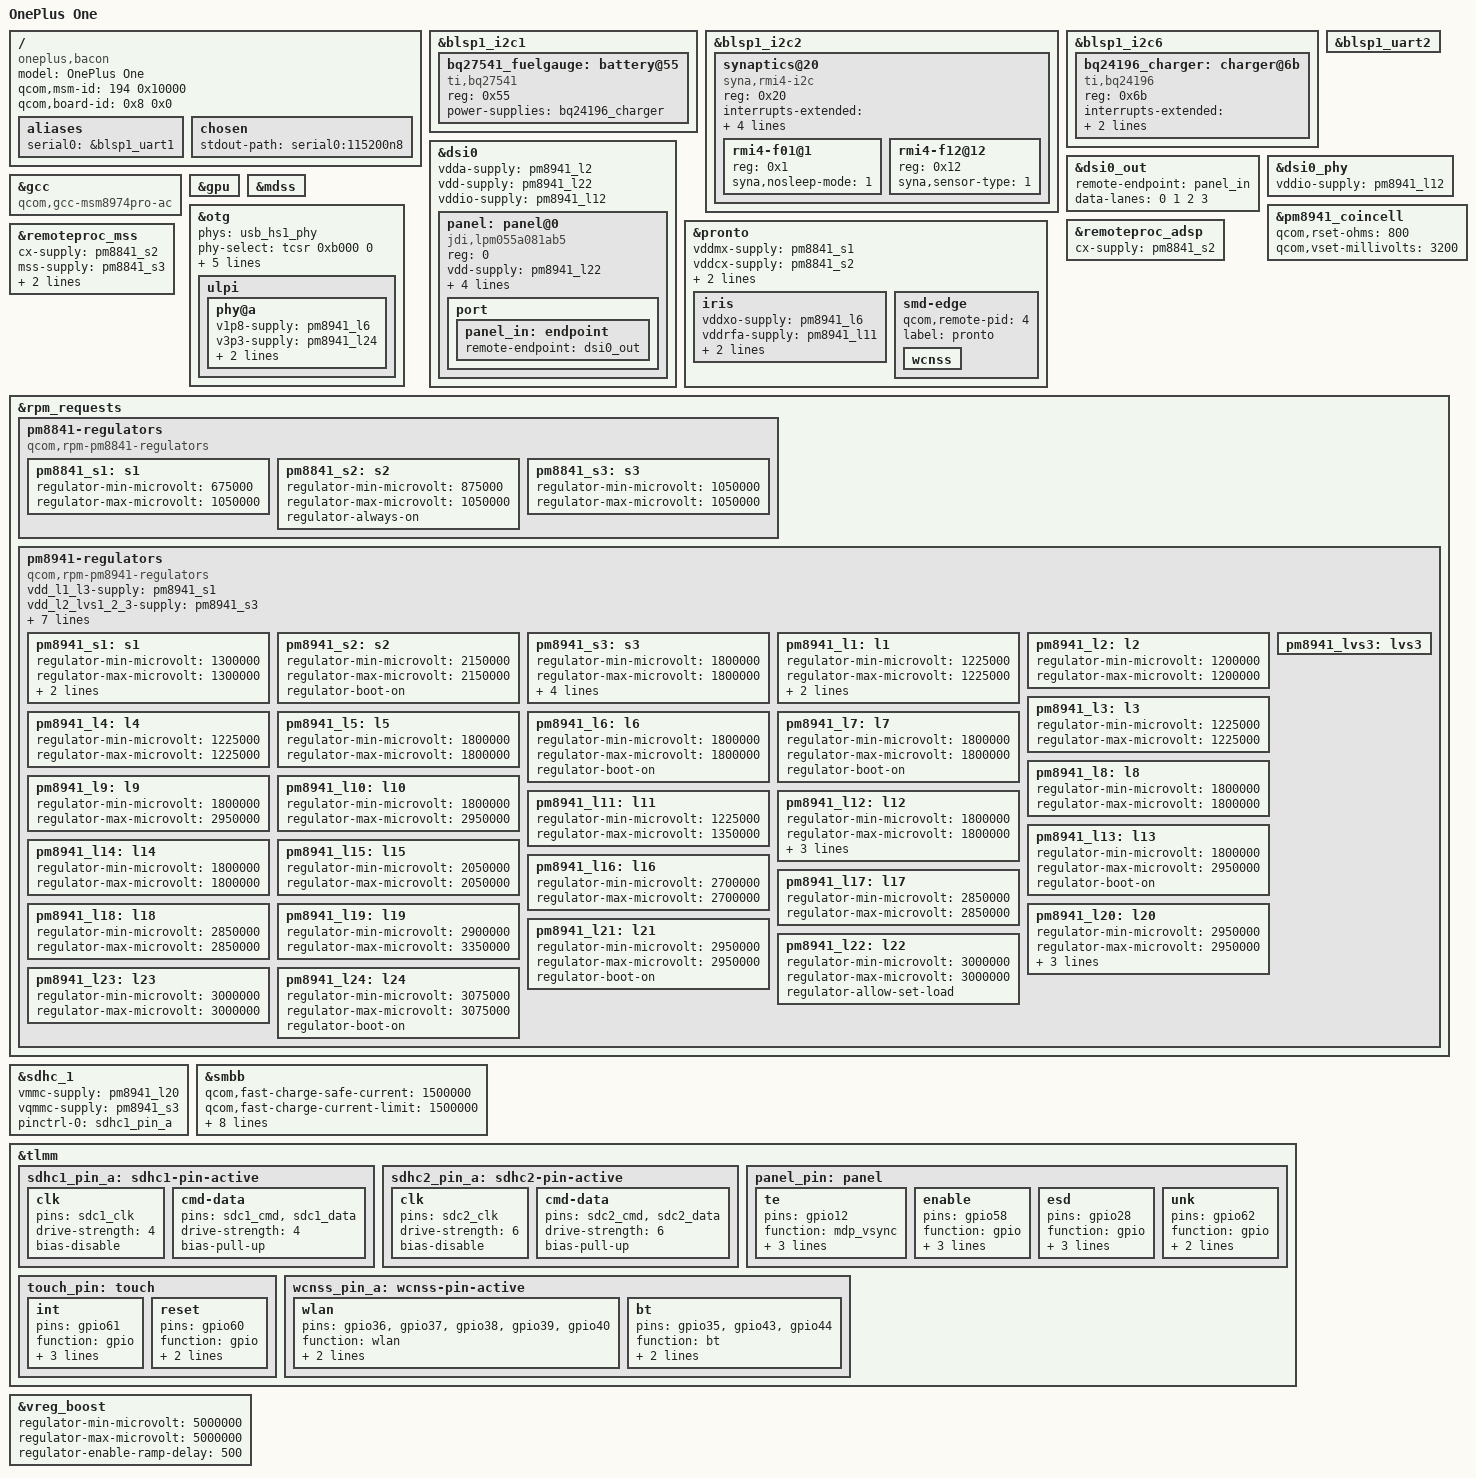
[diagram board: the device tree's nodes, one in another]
// SPDX-License-Identifier: GPL-2.0
#include "qcom-msm8974pro.dtsi"
#include "qcom-pm8841.dtsi"
#include "qcom-pm8941.dtsi"
#include <dt-bindings/input/input.h>
#include <dt-bindings/pinctrl/qcom,pmic-gpio.h>

/ {
	model = "OnePlus One";
	compatible = "oneplus,bacon", "qcom,msm8974";
	qcom,msm-id = <194 0x10000>;
	qcom,board-id = <0x8 0x0>;

	aliases {
		serial0 = &blsp1_uart1;
	};

	chosen {
		stdout-path = "serial0:115200n8";
	};
};

&blsp1_i2c1 {
	status = "okay";

	bq27541_fuelgauge: battery@55 {
		compatible = "ti,bq27541";
		reg = <0x55>;
		power-supplies = <&bq24196_charger>;
	};
};

&blsp1_i2c2 {
	status = "okay";

	synaptics@20 {
		compatible = "syna,rmi4-i2c";
		reg = <0x20>;

		interrupts-extended = <&tlmm 61 IRQ_TYPE_EDGE_FALLING>;
		vdd-supply = <&pm8941_l22>;
		vio-supply = <&pm8941_lvs3>;

		pinctrl-names = "default";
		pinctrl-0 = <&touch_pin>;

		#address-cells = <1>;
		#size-cells = <0>;

		rmi4-f01@1 {
			reg = <0x1>;
			syna,nosleep-mode = <1>;
		};

		rmi4-f12@12 {
			reg = <0x12>;
			syna,sensor-type = <1>;
		};

		// reset tlmm 8
		// other functions available ?
	};
};

&blsp1_i2c6 {
	status = "okay";

	bq24196_charger: charger@6b {
		compatible = "ti,bq24196";
		reg = <0x6b>;
		interrupts-extended = <&tlmm 31 IRQ_TYPE_EDGE_FALLING>;
		omit-battery-class;
	};
};

&blsp1_uart2 {
	status = "okay";
};

&dsi0 {
	status = "okay";

	vdda-supply = <&pm8941_l2>;
	vdd-supply = <&pm8941_l22>;
	vddio-supply = <&pm8941_l12>;

	panel: panel@0 {
		reg = <0>;
		compatible = "jdi,lpm055a081ab5";

		vdd-supply = <&pm8941_l22>;
		vddio-supply = <&pm8941_l12>;

		// backlight?

		enable-gpios = <&tlmm 58 0>;
		reset-gpios = <&pm8941_gpios 19 0>;

		pinctrl-names = "default";
		pinctrl-0 = <&panel_pin>;

		port {
			panel_in: endpoint {
				remote-endpoint = <&dsi0_out>;
			};
		};
	};
};

&dsi0_out {
	remote-endpoint = <&panel_in>;
	data-lanes = <0 1 2 3>;
};

&dsi0_phy {
    status = "okay";

    vddio-supply = <&pm8941_l12>;
};

&gcc {
	compatible = "qcom,gcc-msm8974pro-ac";
};

&gpu {
	status = "okay";
};

&mdss {
	status = "okay";
};

&otg {
	status = "okay";

	phys = <&usb_hs1_phy>;
	phy-select = <&tcsr 0xb000 0>;
	extcon = <&smbb>, <&usb_id>;
	vbus-supply = <&chg_otg>;

	hnp-disable;
	srp-disable;
	adp-disable;

	ulpi {
		phy@a {
			status = "okay";

			v1p8-supply = <&pm8941_l6>;
			v3p3-supply = <&pm8941_l24>;

			extcon = <&smbb>;
			qcom,init-seq = /bits/ 8 <0x1 0x64>;
		};
	};
};

&pm8941_coincell {
	status = "okay";
	qcom,rset-ohms = <800>;
	qcom,vset-millivolts = <3200>;
};

&pronto {
	status = "okay";

	vddmx-supply = <&pm8841_s1>;
	vddcx-supply = <&pm8841_s2>;
	vddpx-supply = <&pm8941_s3>;

	pinctrl-names = "default";
	pinctrl-0 = <&wcnss_pin_a>;

	iris {
		vddxo-supply = <&pm8941_l6>;
		vddrfa-supply = <&pm8941_l11>;
		vddpa-supply = <&pm8941_l19>;
		vdddig-supply = <&pm8941_s3>;
	};

	smd-edge {
		qcom,remote-pid = <4>;
		label = "pronto";

		wcnss {
			status = "okay";
		};
	};
};

&remoteproc_adsp {
	cx-supply = <&pm8841_s2>;
};

&remoteproc_mss {
	cx-supply = <&pm8841_s2>;
	mss-supply = <&pm8841_s3>;
	mx-supply = <&pm8841_s1>;
	pll-supply = <&pm8941_l12>;
};

&rpm_requests {
	pm8841-regulators {
		compatible = "qcom,rpm-pm8841-regulators";

		pm8841_s1: s1 {
			regulator-min-microvolt = <675000>;
			regulator-max-microvolt = <1050000>;
		};

		pm8841_s2: s2 {
			regulator-min-microvolt = <875000>;
			regulator-max-microvolt = <1050000>;
			regulator-always-on;
		};

		pm8841_s3: s3 {
			regulator-min-microvolt = <1050000>;
			regulator-max-microvolt = <1050000>;
		};
	};

	pm8941-regulators {
		compatible = "qcom,rpm-pm8941-regulators";

		vdd_l1_l3-supply = <&pm8941_s1>;
		vdd_l2_lvs1_2_3-supply = <&pm8941_s3>;
		vdd_l4_l11-supply = <&pm8941_s1>;
		vdd_l5_l7-supply = <&pm8941_s2>;
		vdd_l6_l12_l14_l15-supply = <&pm8941_s2>;
		vdd_l8_l16_l18_l19-supply = <&vreg_vph_pwr>;
		vdd_l9_l10_l17_l22-supply = <&pm8941_5v>;
		vdd_l13_l20_l23_l24-supply = <&pm8941_5v>;
		vdd_l21-supply = <&pm8941_5v>;

		pm8941_s1: s1 {
			regulator-min-microvolt = <1300000>;
			regulator-max-microvolt = <1300000>;

			regulator-always-on;
			regulator-boot-on;
		};

		pm8941_s2: s2 {
			regulator-min-microvolt = <2150000>;
			regulator-max-microvolt = <2150000>;

			regulator-boot-on;
		};

		pm8941_s3: s3 {
			regulator-min-microvolt = <1800000>;
			regulator-max-microvolt = <1800000>;
			regulator-system-load = <154000>;

			regulator-always-on;
			regulator-boot-on;
			regulator-allow-set-load;
		};

		pm8941_l1: l1 {
			regulator-min-microvolt = <1225000>;
			regulator-max-microvolt = <1225000>;

			regulator-always-on;
			regulator-boot-on;
		};

		pm8941_l2: l2 {
			regulator-min-microvolt = <1200000>;
			regulator-max-microvolt = <1200000>;
		};

		pm8941_l3: l3 {
			regulator-min-microvolt = <1225000>;
			regulator-max-microvolt = <1225000>;
		};

		pm8941_l4: l4 {
			regulator-min-microvolt = <1225000>;
			regulator-max-microvolt = <1225000>;
		};

		pm8941_l5: l5 {
			regulator-min-microvolt = <1800000>;
			regulator-max-microvolt = <1800000>;
		};

		pm8941_l6: l6 {
			regulator-min-microvolt = <1800000>;
			regulator-max-microvolt = <1800000>;

			regulator-boot-on;
		};

		pm8941_l7: l7 {
			regulator-min-microvolt = <1800000>;
			regulator-max-microvolt = <1800000>;

			regulator-boot-on;
		};

		pm8941_l8: l8 {
			regulator-min-microvolt = <1800000>;
			regulator-max-microvolt = <1800000>;
		};

		pm8941_l9: l9 {
			regulator-min-microvolt = <1800000>;
			regulator-max-microvolt = <2950000>;
		};

		pm8941_l10: l10 {
			regulator-min-microvolt = <1800000>;
			regulator-max-microvolt = <2950000>;
		};

		pm8941_l11: l11 {
			regulator-min-microvolt = <1225000>;
			regulator-max-microvolt = <1350000>;
		};

		pm8941_l12: l12 {
			regulator-min-microvolt = <1800000>;
			regulator-max-microvolt = <1800000>;

			regulator-always-on;
			regulator-boot-on;
			regulator-allow-set-load;
		};

		pm8941_l13: l13 {
			regulator-min-microvolt = <1800000>;
			regulator-max-microvolt = <2950000>;

			regulator-boot-on;
		};

		pm8941_l14: l14 {
			regulator-min-microvolt = <1800000>;
			regulator-max-microvolt = <1800000>;
		};

		pm8941_l15: l15 {
			regulator-min-microvolt = <2050000>;
			regulator-max-microvolt = <2050000>;
		};

		pm8941_l16: l16 {
			regulator-min-microvolt = <2700000>;
			regulator-max-microvolt = <2700000>;
		};

		pm8941_l17: l17 {
			regulator-min-microvolt = <2850000>;
			regulator-max-microvolt = <2850000>;
		};

		pm8941_l18: l18 {
			regulator-min-microvolt = <2850000>;
			regulator-max-microvolt = <2850000>;
		};

		pm8941_l19: l19 {
			regulator-min-microvolt = <2900000>;
			regulator-max-microvolt = <3350000>;
		};

		pm8941_l20: l20 {
			regulator-min-microvolt = <2950000>;
			regulator-max-microvolt = <2950000>;

			regulator-system-load = <200000>;
			regulator-allow-set-load;
			regulator-boot-on;
		};

		pm8941_l21: l21 {
			regulator-min-microvolt = <2950000>;
			regulator-max-microvolt = <2950000>;

			regulator-boot-on;
		};

		pm8941_l22: l22 {
			regulator-min-microvolt = <3000000>;
			regulator-max-microvolt = <3000000>;
			regulator-allow-set-load;
		};

		pm8941_l23: l23 {
			regulator-min-microvolt = <3000000>;
			regulator-max-microvolt = <3000000>;
		};

		pm8941_l24: l24 {
			regulator-min-microvolt = <3075000>;
			regulator-max-microvolt = <3075000>;

			regulator-boot-on;
		};

		pm8941_lvs3: lvs3 {};
	};
};

&sdhc_1 {
	status = "okay";

	vmmc-supply = <&pm8941_l20>;
	vqmmc-supply = <&pm8941_s3>;

	pinctrl-names = "default";
	pinctrl-0 = <&sdhc1_pin_a>;
};

&smbb {
	qcom,fast-charge-safe-current = <1500000>;
	qcom,fast-charge-current-limit = <1500000>;
	qcom,dc-current-limit = <1800000>;
	qcom,fast-charge-safe-voltage = <4400000>;
	qcom,fast-charge-high-threshold-voltage = <4350000>;
	qcom,fast-charge-low-threshold-voltage = <3400000>;
	qcom,auto-recharge-threshold-voltage = <4200000>;
	qcom,minimum-input-voltage = <4400000>;
};

&tlmm {
	sdhc1_pin_a: sdhc1-pin-active {
		clk {
			pins = "sdc1_clk";
			drive-strength = <4>;
			bias-disable;
		};

		cmd-data {
			pins = "sdc1_cmd", "sdc1_data";
			drive-strength = <4>;
			bias-pull-up;
		};
	};

	sdhc2_pin_a: sdhc2-pin-active {
		clk {
			pins = "sdc2_clk";
			drive-strength = <6>;
			bias-disable;
		};

		cmd-data {
			pins = "sdc2_cmd", "sdc2_data";
			drive-strength = <6>;
			bias-pull-up;
		};
	};

	panel_pin: panel {
		te {
			pins = "gpio12";
			function = "mdp_vsync";
			drive-strength = <2>;
			bias-pull-down;
			input-enable;
		};

		enable {
			pins = "gpio58";
			function = "gpio";
			drive-strength = <8>;
			bias-disable;
			output-high;
		};

		esd {
			pins = "gpio28";
			function = "gpio";
			drive-strength = <2>;
			bias-pull-down;
			input-enable;
		};

		unk {
			pins = "gpio62";
			function = "gpio";
			bias-disable;
			output-low;
		};
	};

	touch_pin: touch {
		int {
			pins = "gpio61";
			function = "gpio";
			drive-strength = <2>;
			bias-disable;
			input-enable;
		};

		reset {
			pins = "gpio60";
			function = "gpio";
			drive-strength = <2>;
			bias-pull-up;
		};
	};

	wcnss_pin_a: wcnss-pin-active {
		wlan {
			pins = "gpio36", "gpio37", "gpio38", "gpio39", "gpio40";
			function = "wlan";
			drive-strength = <6>;
			bias-pull-down;
		};

		bt {
			pins = "gpio35", "gpio43", "gpio44";
			function = "bt";
			drive-strength = <2>;
			bias-pull-down;
		};
	};
};

&vreg_boost {
	regulator-min-microvolt = <5000000>;
	regulator-max-microvolt = <5000000>;
	regulator-enable-ramp-delay = <500>;
};
